# MSP430FR4133 register map
Registers are 16-bit, read-write, reset 0x0 unless marked. A register's access mark holds for its fields unless they carry their own. Offsets are from the block's base; [hi:lo] are bit positions; {n}, {i} and the like mark numbered series.

## CS — CS Clock System
Base 0x00000180
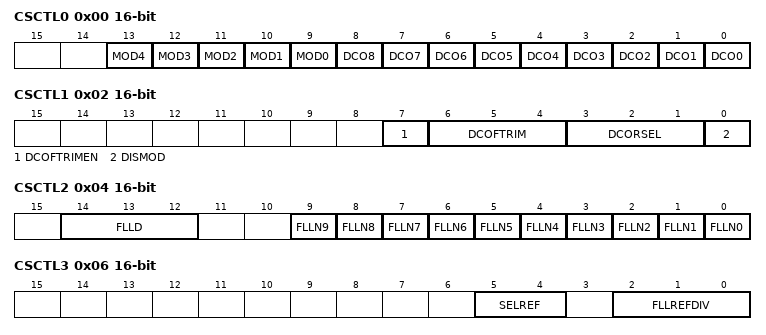
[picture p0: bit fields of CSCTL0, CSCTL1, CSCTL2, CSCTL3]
0x00 CSCTL0 — CS Control Register 0
  [n+9] MOD{n} (n=0..4) — Modulation Bit Counter Bit : {n}
  [n] DCO{n} (n=0..8) — DCO TAP Bit : {n}
0x02 CSCTL1 — CS Control Register 1
  [7] DCOFTRIMEN — DCO frequency trim enable
  [6:4] DCOFTRIM — DCO frequency trim. Bit: 0
    {v}=DCO frequency trim: {v} (v=0..7)
  [3:1] DCORSEL — DCO frequency range select Bit: 0
    {v}=DCO frequency range select: {v} (v=0..7)
  [0] DISMOD — Disable Modulation
0x04 CSCTL2 — CS Control Register 2
  [14:12] FLLD — Loop Divider Bit : 0
    0=Multiply Selected Loop Freq. By 1; 1=Multiply Selected Loop Freq. By 2; 2=Multiply Selected Loop Freq. By 4; 3=Multiply Selected Loop Freq. By 8; 4=Multiply Selected Loop Freq. By 16; 5=Multiply Selected Loop Freq. By 32
  [n] FLLN{n} (n=0..9) — FLL Multipier Bit : {n}
0x06 CSCTL3 — CS Control Register 3
  [5:4] SELREF — FLL Reference Clock Select Bit : 0
    {v}=FLL Reference Clock Select {v} (v=0..3)
  [2:0] FLLREFDIV — Reference Divider Bit : 0
    0=Reference Divider: f(LFCLK)/1; 1=Reference Divider: f(LFCLK)/2; 2=Reference Divider: f(LFCLK)/4; 3=Reference Divider: f(LFCLK)/8; 4=Reference Divider: f(LFCLK)/12; 5=Reference Divider: f(LFCLK)/16; 6=Reference Divider: f(LFCLK)/16; 7=Reference Divider: f(LFCLK)/16
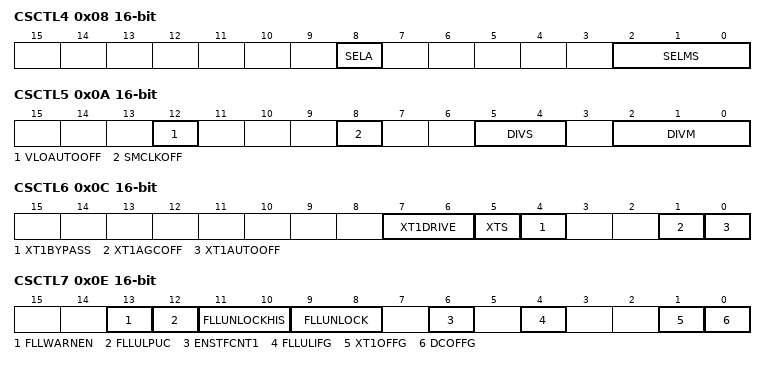
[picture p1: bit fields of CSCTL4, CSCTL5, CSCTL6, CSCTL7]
0x08 CSCTL4 — CS Control Register 4
  [8] SELA — ACLK Source Select Bit: 0
  [2:0] SELMS — MCLK and SMCLK Source Select Bit: 0
    {v}=MCLK and SMCLK Source Select {v} (v=0..7)
0x0A CSCTL5 — CS Control Register 5
  [12] VLOAUTOOFF — VLO automatic off enable
  [8] SMCLKOFF
  [5:4] DIVS — SMCLK Divider Bit: 0
    {v}=SMCLK Source Divider {v} (v=0..3)
  [2:0] DIVM — MCLK Divider Bit: 0
    {v}=MCLK Source Divider {v} (v=0..7)
0x0C CSCTL6 — CS Control Register 6
  [7:6] XT1DRIVE — XT1 Drive Level mode Bit 0
    {v}=XT1 Drive Level mode: {v} (v=0..3)
  [5] XTS — 1: Selects high-freq. oscillator
  [4] XT1BYPASS — XT1 bypass mode : 0: internal 1:sourced from external pin
  [1] XT1AGCOFF — XT1 Automatic Gain Control (AGC) disable
  [0] XT1AUTOOFF — XT1 automatic off enable
0x0E CSCTL7 — CS Control Register 7
  [13] FLLWARNEN — Warning enable
  [12] FLLULPUC — FLL unlock PUC enable
  [11:10] FLLUNLOCKHIS — Unlock history Bit: 0
    {v}=Unlock history: {v} (v=0..3)
  [9:8] FLLUNLOCK — FLL unlock condition Bit: 0
    {v}=FLL unlock condition: {v} (v=0..3)
  [6] ENSTFCNT1 — Enable start counter for XT1
  [4] FLLULIFG — FLL unlock interrupt flag
  [1] XT1OFFG — XT1 Low Frequency Oscillator Fault Flag
  [0] DCOFFG — DCO fault flag
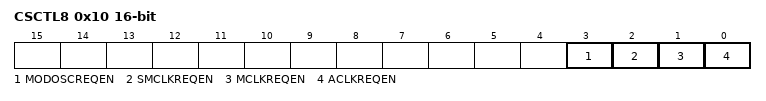
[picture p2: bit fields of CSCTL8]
0x10 CSCTL8 — CS Control Register 8
  [3] MODOSCREQEN — MODOSC Clock Request Enable
  [2] SMCLKREQEN — SMCLK Clock Request Enable
  [1] MCLKREQEN — MCLK Clock Request Enable
  [0] ACLKREQEN — ACLK Clock Request Enable

## FRAM
Base 0x000001A0
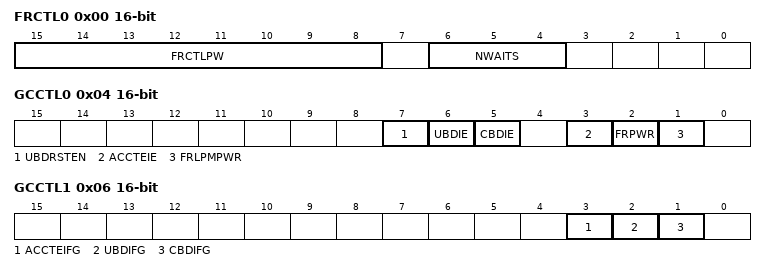
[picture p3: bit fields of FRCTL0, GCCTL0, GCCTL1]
0x00 FRCTL0 — FRAM Controller Control 0
  [15:8] FRCTLPW — FRCTLPW Password
    on read: 150=PASSWORD (Value always reads from the FRCTL0 register) | on write: 165=PASSWORD (Value which must be written to the FRCTL0 register)
  [6:4] NWAITS — FRAM Wait state control Bit: 0
    {v}=FRAM Wait state control: {v} (v=0..7)
0x04 GCCTL0 — General Control 0
  [7] UBDRSTEN — Enable Power Up Clear (PUC) reset if FRAM uncorrectable bit error detected
  [6] UBDIE — Enable NMI event if uncorrectable bit error detected
  [5] CBDIE — Enable NMI event if correctable bit error detected
  [3] ACCTEIE — RESERVED
  [2] FRPWR — FRAM Power Control
  [1] FRLPMPWR — FRAM Enable FRAM auto power up after LPM
0x06 GCCTL1 — General Control 1
  [3] ACCTEIFG — Access time error flag
  [2] UBDIFG — FRAM uncorrectable bit error flag
  [1] CBDIFG — FRAM correctable bit error flag

## CRC16
Base 0x000001C0
0x00 CRCDI — CRC Data In Register
0x02 CRCDIRB — CRC data in reverse byte Register
0x04 CRCINIRES — CRC Initialisation Register and Result Register
0x06 CRCRESR — CRC reverse result Register
